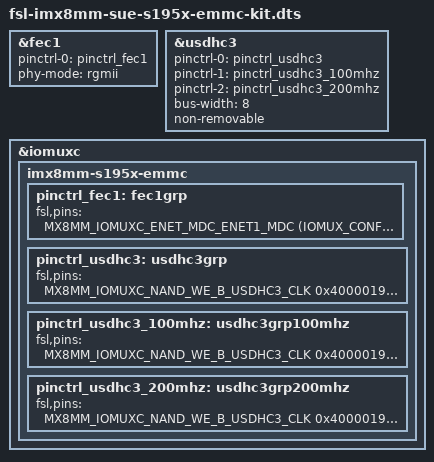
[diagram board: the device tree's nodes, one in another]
/dts-v1/;

#include "fsl-imx8mm-sue-s195x-common.dtsi"

&fec1 {
	pinctrl-names = "default";
	pinctrl-0 = <&pinctrl_fec1>;
	status = "okay";
	phy-mode = "rgmii";
};

&usdhc3 {
	pinctrl-names = "default", "state_100mhz", "state_200mhz";
	pinctrl-0 = <&pinctrl_usdhc3>;
	pinctrl-1 = <&pinctrl_usdhc3_100mhz>;
	pinctrl-2 = <&pinctrl_usdhc3_200mhz>;
	bus-width = <8>;
	non-removable;
	status = "okay";
};

&iomuxc {
	imx8mm-s195x-emmc {
		pinctrl_fec1: fec1grp {
			fsl,pins = <
				MX8MM_IOMUXC_ENET_MDC_ENET1_MDC			(IOMUX_CONFIG_SION | PAD_CTL_DSE6x)
				MX8MM_IOMUXC_ENET_MDIO_ENET1_MDIO		(PAD_CTL_DSE6x)

				MX8MM_IOMUXC_ENET_TD0_ENET1_RGMII_TD0		(PAD_CTL_FAST | PAD_CTL_DSE6x)
				MX8MM_IOMUXC_ENET_TD1_ENET1_RGMII_TD1		(PAD_CTL_FAST | PAD_CTL_DSE6x)
				MX8MM_IOMUXC_ENET_TD2_ENET1_RGMII_TD2		(PAD_CTL_FAST | PAD_CTL_DSE6x)
				MX8MM_IOMUXC_ENET_TD3_ENET1_RGMII_TD3		(PAD_CTL_FAST | PAD_CTL_DSE6x)
				MX8MM_IOMUXC_ENET_TX_CTL_ENET1_RGMII_TX_CTL	(PAD_CTL_FAST | PAD_CTL_DSE6x)
				MX8MM_IOMUXC_ENET_TXC_ENET1_RGMII_TXC		(PAD_CTL_FAST | PAD_CTL_DSE6x)

				MX8MM_IOMUXC_ENET_RD0_ENET1_RGMII_RD0		(PAD_CTL_HYS | PAD_CTL_FAST)
				MX8MM_IOMUXC_ENET_RD1_ENET1_RGMII_RD1		(PAD_CTL_HYS | PAD_CTL_FAST)
				MX8MM_IOMUXC_ENET_RD2_ENET1_RGMII_RD2		(PAD_CTL_HYS | PAD_CTL_FAST)
				MX8MM_IOMUXC_ENET_RD3_ENET1_RGMII_RD3		(PAD_CTL_HYS | PAD_CTL_FAST)
				MX8MM_IOMUXC_ENET_RX_CTL_ENET1_RGMII_RX_CTL	(PAD_CTL_HYS | PAD_CTL_FAST)
				MX8MM_IOMUXC_ENET_RXC_ENET1_RGMII_RXC		(PAD_CTL_HYS | PAD_CTL_FAST)

				MX8MM_IOMUXC_GPIO1_IO00_GPIO1_IO0		(PAD_CTL_PE_UP)					/* ENET_RST_N */
				MX8MM_IOMUXC_GPIO1_IO09_GPIO1_IO9		(PAD_CTL_PE_DOWN)				/* ENET_PDONW_N */

			>;
		};

		pinctrl_usdhc3: usdhc3grp {
			fsl,pins = <
				MX8MM_IOMUXC_NAND_WE_B_USDHC3_CLK		0x40000190
				MX8MM_IOMUXC_NAND_WP_B_USDHC3_CMD		0x1d0
				MX8MM_IOMUXC_NAND_DATA04_USDHC3_DATA0		0x1d0
				MX8MM_IOMUXC_NAND_DATA05_USDHC3_DATA1		0x1d0
				MX8MM_IOMUXC_NAND_DATA06_USDHC3_DATA2		0x1d0
				MX8MM_IOMUXC_NAND_DATA07_USDHC3_DATA3		0x1d0
				MX8MM_IOMUXC_NAND_RE_B_USDHC3_DATA4		0x1d0
				MX8MM_IOMUXC_NAND_CE2_B_USDHC3_DATA5		0x1d0
				MX8MM_IOMUXC_NAND_CE3_B_USDHC3_DATA6		0x1d0
				MX8MM_IOMUXC_NAND_CLE_USDHC3_DATA7		0x1d0
				MX8MM_IOMUXC_NAND_CE1_B_USDHC3_STROBE 		0x190
			>;
		};

		pinctrl_usdhc3_100mhz: usdhc3grp100mhz {
			fsl,pins = <
				MX8MM_IOMUXC_NAND_WE_B_USDHC3_CLK		0x40000194
				MX8MM_IOMUXC_NAND_WP_B_USDHC3_CMD		0x1d4
				MX8MM_IOMUXC_NAND_DATA04_USDHC3_DATA0		0x1d4
				MX8MM_IOMUXC_NAND_DATA05_USDHC3_DATA1		0x1d4
				MX8MM_IOMUXC_NAND_DATA06_USDHC3_DATA2		0x1d4
				MX8MM_IOMUXC_NAND_DATA07_USDHC3_DATA3		0x1d4
				MX8MM_IOMUXC_NAND_RE_B_USDHC3_DATA4		0x1d4
				MX8MM_IOMUXC_NAND_CE2_B_USDHC3_DATA5		0x1d4
				MX8MM_IOMUXC_NAND_CE3_B_USDHC3_DATA6		0x1d4
				MX8MM_IOMUXC_NAND_CLE_USDHC3_DATA7		0x1d4
				MX8MM_IOMUXC_NAND_CE1_B_USDHC3_STROBE 		0x194
			>;
		};

		pinctrl_usdhc3_200mhz: usdhc3grp200mhz {
			fsl,pins = <
				MX8MM_IOMUXC_NAND_WE_B_USDHC3_CLK		0x40000196
				MX8MM_IOMUXC_NAND_WP_B_USDHC3_CMD		0x1d6
				MX8MM_IOMUXC_NAND_DATA04_USDHC3_DATA0		0x1d6
				MX8MM_IOMUXC_NAND_DATA05_USDHC3_DATA1		0x1d6
				MX8MM_IOMUXC_NAND_DATA06_USDHC3_DATA2		0x1d6
				MX8MM_IOMUXC_NAND_DATA07_USDHC3_DATA3		0x1d6
				MX8MM_IOMUXC_NAND_RE_B_USDHC3_DATA4		0x1d6
				MX8MM_IOMUXC_NAND_CE2_B_USDHC3_DATA5		0x1d6
				MX8MM_IOMUXC_NAND_CE3_B_USDHC3_DATA6		0x1d6
				MX8MM_IOMUXC_NAND_CLE_USDHC3_DATA7		0x1d6
				MX8MM_IOMUXC_NAND_CE1_B_USDHC3_STROBE 		0x196
			>;
		};
	};
};

